VERSION ""

NS_ :

BS_:

BU_:

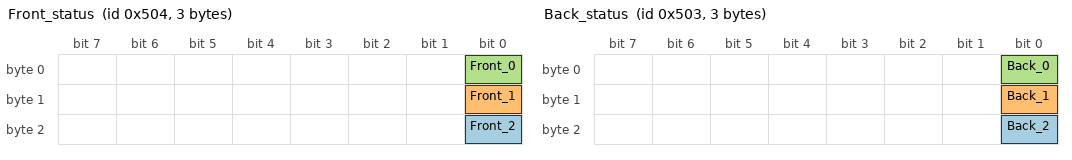
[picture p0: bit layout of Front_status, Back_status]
BO_ 1284 Front_status: 3 Vector__XXX
 SG_ Front_2 : 16|1@1+ (1,0) [0|1] "" Vector__XXX
 SG_ Front_1 : 8|1@1+ (1,0) [0|1] "" Vector__XXX
 SG_ Front_0 : 0|1@1+ (1,0) [0|1] "" Vector__XXX

BO_ 1283 Back_status: 3 Vector__XXX
 SG_ Back_2 : 16|1@1+ (1,0) [0|1] "" Vector__XXX
 SG_ Back_1 : 8|1@1+ (1,0) [0|1] "" Vector__XXX
 SG_ Back_0 : 0|1@1+ (1,0) [0|1] "" Vector__XXX

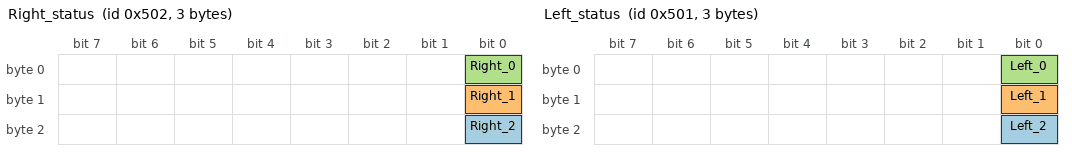
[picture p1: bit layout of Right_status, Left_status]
BO_ 1282 Right_status: 3 Vector__XXX
 SG_ Right_2 : 16|1@1+ (1,0) [0|1] "" Vector__XXX
 SG_ Right_1 : 8|1@1+ (1,0) [0|1] "" Vector__XXX
 SG_ Right_0 : 0|1@1+ (1,0) [0|1] "" Vector__XXX

BO_ 1281 Left_status: 3 Vector__XXX
 SG_ Left_2 : 16|1@1+ (1,0) [0|1] "" Vector__XXX
 SG_ Left_1 : 8|1@1+ (1,0) [0|1] "" Vector__XXX
 SG_ Left_0 : 0|1@1+ (1,0) [0|1] "" Vector__XXX

BO_ 1024 Led_status: 2 Vector__XXX
 SG_ Right_led : 8|1@1+ (1,0) [0|1] "" Vector__XXX
 SG_ Left_led : 0|1@1+ (1,0) [0|1] "" Vector__XXX

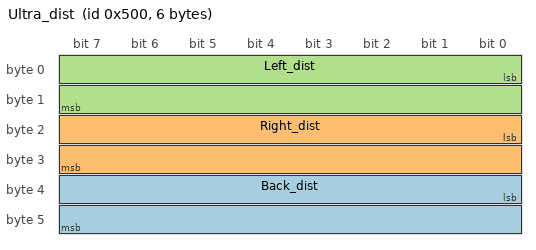
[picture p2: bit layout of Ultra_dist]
BO_ 1280 Ultra_dist: 6 Vector__XXX
 SG_ Back_dist : 32|16@1+ (1,0) [0|30] "cm" Vector__XXX
 SG_ Right_dist : 16|16@1+ (1,0) [0|30] "cm" Vector__XXX
 SG_ Left_dist : 0|16@1+ (1,0) [0|30] "cm" Vector__XXX

BO_ 1792 Tof_dist: 2 Vector__XXX
 SG_ Front_dist : 0|16@1+ (1,0) [0|30] "cm" Vector__XXX

BO_ 1536 RPM_status: 8 Vector__XXX
 SG_ Right_rpm : 32|32@1- (1,0) [0|8000] "rpm" Vector__XXX
 SG_ Left_rpm : 0|32@1- (1,0) [0|8000] "rpm" Vector__XXX

BA_DEF_  "BusType" STRING ;
BA_DEF_DEF_  "BusType" "CAN";
